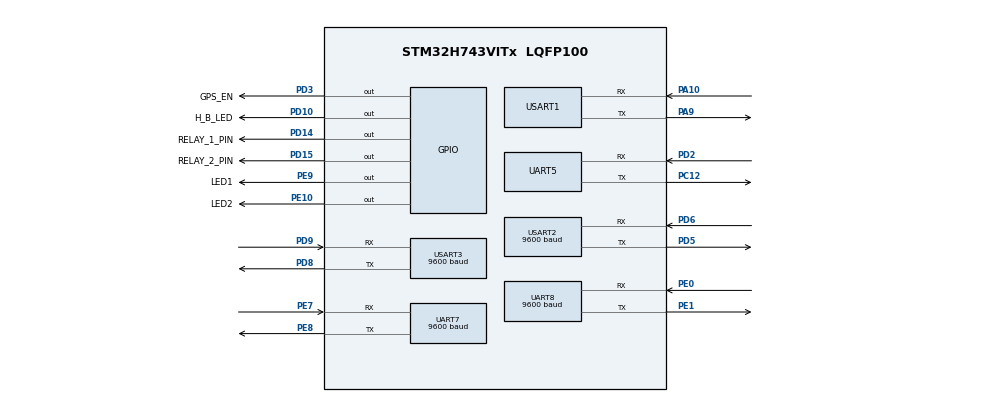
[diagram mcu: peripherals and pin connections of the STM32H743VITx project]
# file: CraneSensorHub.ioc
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CORTEX_M7.default_mode_Activation=1
Dma.Request0=UART7_RX
Dma.Request1=UART7_TX
Dma.Request2=USART1_RX
Dma.Request3=USART1_TX
Dma.Request4=USART2_RX
Dma.Request5=USART2_TX
Dma.Request6=UART5_RX
Dma.Request7=UART5_TX
Dma.UART5_RX.6.Direction=DMA_PERIPH_TO_MEMORY
Dma.UART5_RX.6.EventEnable=DISABLE
Dma.UART5_RX.6.FIFOMode=DMA_FIFOMODE_DISABLE
Dma.UART5_RX.6.Instance=DMA1_Stream6
Dma.UART5_RX.6.MemDataAlignment=DMA_MDATAALIGN_BYTE
Dma.UART5_RX.6.MemInc=DMA_MINC_ENABLE
Dma.UART5_RX.6.Mode=DMA_NORMAL
Dma.UART5_RX.6.PeriphDataAlignment=DMA_PDATAALIGN_BYTE
Dma.UART5_RX.6.PeriphInc=DMA_PINC_DISABLE
Dma.UART5_RX.6.Polarity=HAL_DMAMUX_REQ_GEN_RISING
Dma.UART5_RX.6.Priority=DMA_PRIORITY_LOW
Dma.UART5_RX.6.RequestNumber=1
Dma.UART5_RX.6.SignalID=NONE
Dma.UART5_RX.6.SyncEnable=DISABLE
Dma.UART5_RX.6.SyncPolarity=HAL_DMAMUX_SYNC_NO_EVENT
Dma.UART5_RX.6.SyncRequestNumber=1
Dma.UART5_RX.6.SyncSignalID=NONE
Dma.UART5_TX.7.Direction=DMA_MEMORY_TO_PERIPH
Dma.UART5_TX.7.EventEnable=DISABLE
Dma.UART5_TX.7.FIFOMode=DMA_FIFOMODE_DISABLE
Dma.UART5_TX.7.Instance=DMA1_Stream7
Dma.UART5_TX.7.MemDataAlignment=DMA_MDATAALIGN_BYTE
Dma.UART5_TX.7.MemInc=DMA_MINC_ENABLE
Dma.UART5_TX.7.Mode=DMA_NORMAL
Dma.UART5_TX.7.PeriphDataAlignment=DMA_PDATAALIGN_BYTE
Dma.UART5_TX.7.PeriphInc=DMA_PINC_DISABLE
Dma.UART5_TX.7.Polarity=HAL_DMAMUX_REQ_GEN_RISING
Dma.UART5_TX.7.Priority=DMA_PRIORITY_LOW
Dma.UART5_TX.7.RequestNumber=1
Dma.UART5_TX.7.SignalID=NONE
Dma.UART5_TX.7.SyncEnable=DISABLE
Dma.UART5_TX.7.SyncPolarity=HAL_DMAMUX_SYNC_NO_EVENT
Dma.UART5_TX.7.SyncRequestNumber=1
Dma.UART5_TX.7.SyncSignalID=NONE
Dma.UART7_RX.0.Direction=DMA_PERIPH_TO_MEMORY
Dma.UART7_RX.0.EventEnable=DISABLE
Dma.UART7_RX.0.FIFOMode=DMA_FIFOMODE_DISABLE
Dma.UART7_RX.0.Instance=DMA1_Stream0
Dma.UART7_RX.0.MemDataAlignment=DMA_MDATAALIGN_BYTE
Dma.UART7_RX.0.MemInc=DMA_MINC_ENABLE
Dma.UART7_RX.0.Mode=DMA_NORMAL
Dma.UART7_RX.0.PeriphDataAlignment=DMA_PDATAALIGN_BYTE
Dma.UART7_RX.0.PeriphInc=DMA_PINC_DISABLE
Dma.UART7_RX.0.Polarity=HAL_DMAMUX_REQ_GEN_RISING
Dma.UART7_RX.0.Priority=DMA_PRIORITY_HIGH
Dma.UART7_RX.0.RequestNumber=1
Dma.UART7_RX.0.SignalID=NONE
Dma.UART7_RX.0.SyncEnable=DISABLE
Dma.UART7_RX.0.SyncPolarity=HAL_DMAMUX_SYNC_NO_EVENT
Dma.UART7_RX.0.SyncRequestNumber=1
Dma.UART7_RX.0.SyncSignalID=NONE
Dma.UART7_TX.1.Direction=DMA_MEMORY_TO_PERIPH
Dma.UART7_TX.1.EventEnable=DISABLE
Dma.UART7_TX.1.FIFOMode=DMA_FIFOMODE_DISABLE
Dma.UART7_TX.1.Instance=DMA1_Stream1
Dma.UART7_TX.1.MemDataAlignment=DMA_MDATAALIGN_BYTE
Dma.UART7_TX.1.MemInc=DMA_MINC_ENABLE
Dma.UART7_TX.1.Mode=DMA_NORMAL
Dma.UART7_TX.1.PeriphDataAlignment=DMA_PDATAALIGN_BYTE
Dma.UART7_TX.1.PeriphInc=DMA_PINC_DISABLE
Dma.UART7_TX.1.Polarity=HAL_DMAMUX_REQ_GEN_RISING
Dma.UART7_TX.1.Priority=DMA_PRIORITY_LOW
Dma.UART7_TX.1.RequestNumber=1
Dma.UART7_TX.1.SignalID=NONE
Dma.UART7_TX.1.SyncEnable=DISABLE
Dma.UART7_TX.1.SyncPolarity=HAL_DMAMUX_SYNC_NO_EVENT
Dma.UART7_TX.1.SyncRequestNumber=1
Dma.UART7_TX.1.SyncSignalID=NONE
Dma.USART1_RX.2.Direction=DMA_PERIPH_TO_MEMORY
Dma.USART1_RX.2.EventEnable=DISABLE
Dma.USART1_RX.2.FIFOMode=DMA_FIFOMODE_DISABLE
Dma.USART1_RX.2.Instance=DMA1_Stream2
Dma.USART1_RX.2.MemDataAlignment=DMA_MDATAALIGN_BYTE
Dma.USART1_RX.2.MemInc=DMA_MINC_ENABLE
Dma.USART1_RX.2.Mode=DMA_NORMAL
Dma.USART1_RX.2.PeriphDataAlignment=DMA_PDATAALIGN_BYTE
Dma.USART1_RX.2.PeriphInc=DMA_PINC_DISABLE
Dma.USART1_RX.2.Polarity=HAL_DMAMUX_REQ_GEN_RISING
Dma.USART1_RX.2.Priority=DMA_PRIORITY_LOW
Dma.USART1_RX.2.RequestNumber=1
Dma.USART1_RX.2.SignalID=NONE
Dma.USART1_RX.2.SyncEnable=DISABLE
Dma.USART1_RX.2.SyncPolarity=HAL_DMAMUX_SYNC_NO_EVENT
Dma.USART1_RX.2.SyncRequestNumber=1
Dma.USART1_RX.2.SyncSignalID=NONE
Dma.USART1_TX.3.Direction=DMA_MEMORY_TO_PERIPH
Dma.USART1_TX.3.EventEnable=DISABLE
Dma.USART1_TX.3.FIFOMode=DMA_FIFOMODE_DISABLE
Dma.USART1_TX.3.Instance=DMA1_Stream3
Dma.USART1_TX.3.MemDataAlignment=DMA_MDATAALIGN_BYTE
Dma.USART1_TX.3.MemInc=DMA_MINC_ENABLE
Dma.USART1_TX.3.Mode=DMA_NORMAL
Dma.USART1_TX.3.PeriphDataAlignment=DMA_PDATAALIGN_BYTE
Dma.USART1_TX.3.PeriphInc=DMA_PINC_DISABLE
Dma.USART1_TX.3.Polarity=HAL_DMAMUX_REQ_GEN_RISING
Dma.USART1_TX.3.Priority=DMA_PRIORITY_LOW
Dma.USART1_TX.3.RequestNumber=1
Dma.USART1_TX.3.SignalID=NONE
Dma.USART1_TX.3.SyncEnable=DISABLE
Dma.USART1_TX.3.SyncPolarity=HAL_DMAMUX_SYNC_NO_EVENT
Dma.USART1_TX.3.SyncRequestNumber=1
Dma.USART1_TX.3.SyncSignalID=NONE
Dma.USART2_RX.4.Direction=DMA_PERIPH_TO_MEMORY
Dma.USART2_RX.4.EventEnable=DISABLE
Dma.USART2_RX.4.FIFOMode=DMA_FIFOMODE_DISABLE
Dma.USART2_RX.4.Instance=DMA1_Stream4
Dma.USART2_RX.4.MemDataAlignment=DMA_MDATAALIGN_BYTE
Dma.USART2_RX.4.MemInc=DMA_MINC_ENABLE
Dma.USART2_RX.4.Mode=DMA_NORMAL
Dma.USART2_RX.4.PeriphDataAlignment=DMA_PDATAALIGN_BYTE
Dma.USART2_RX.4.PeriphInc=DMA_PINC_DISABLE
Dma.USART2_RX.4.Polarity=HAL_DMAMUX_REQ_GEN_RISING
Dma.USART2_RX.4.Priority=DMA_PRIORITY_LOW
Dma.USART2_RX.4.RequestNumber=1
Dma.USART2_RX.4.SignalID=NONE
Dma.USART2_RX.4.SyncEnable=DISABLE
Dma.USART2_RX.4.SyncPolarity=HAL_DMAMUX_SYNC_NO_EVENT
Dma.USART2_RX.4.SyncRequestNumber=1
Dma.USART2_RX.4.SyncSignalID=NONE
Dma.USART2_TX.5.Direction=DMA_MEMORY_TO_PERIPH
Dma.USART2_TX.5.EventEnable=DISABLE
Dma.USART2_TX.5.FIFOMode=DMA_FIFOMODE_DISABLE
Dma.USART2_TX.5.Instance=DMA1_Stream5
Dma.USART2_TX.5.MemDataAlignment=DMA_MDATAALIGN_BYTE
Dma.USART2_TX.5.MemInc=DMA_MINC_ENABLE
Dma.USART2_TX.5.Mode=DMA_NORMAL
Dma.USART2_TX.5.PeriphDataAlignment=DMA_PDATAALIGN_BYTE
Dma.USART2_TX.5.PeriphInc=DMA_PINC_DISABLE
Dma.USART2_TX.5.Polarity=HAL_DMAMUX_REQ_GEN_RISING
Dma.USART2_TX.5.Priority=DMA_PRIORITY_LOW
Dma.USART2_TX.5.RequestNumber=1
Dma.USART2_TX.5.SignalID=NONE
Dma.USART2_TX.5.SyncEnable=DISABLE
Dma.USART2_TX.5.SyncPolarity=HAL_DMAMUX_SYNC_NO_EVENT
Dma.USART2_TX.5.SyncRequestNumber=1
Dma.USART2_TX.5.SyncSignalID=NONE
FREERTOS.Tasks01=defaultTask,24,128,StartDefaultTask,Default,NULL,Dynamic,NULL,NULL
FREERTOS.configUSE_NEWLIB_REENTRANT=1
Mcu.Family=STM32H7
Mcu.Name=STM32H743VITx
Mcu.Package=LQFP100
NVIC.DMA1_Stream0_IRQn=true\:5\:0\:false\:false\:true\:true\:false\:true\:true
NVIC.DMA1_Stream1_IRQn=true\:5\:0\:false\:false\:true\:true\:false\:true\:true
NVIC.DMA1_Stream2_IRQn=true\:5\:0\:false\:false\:true\:true\:false\:true\:true
NVIC.DMA1_Stream3_IRQn=true\:5\:0\:false\:false\:true\:true\:false\:true\:true
NVIC.DMA1_Stream4_IRQn=true\:5\:0\:false\:false\:true\:true\:false\:true\:true
NVIC.DMA1_Stream5_IRQn=true\:5\:0\:false\:false\:true\:true\:false\:true\:true
NVIC.DMA1_Stream6_IRQn=true\:5\:0\:false\:false\:true\:true\:false\:true\:true
NVIC.DMA1_Stream7_IRQn=true\:5\:0\:false\:false\:true\:true\:false\:true\:true
NVIC.PriorityGroup=NVIC_PRIORITYGROUP_4
NVIC.RTC_Alarm_IRQn=true\:5\:0\:false\:false\:true\:true\:true\:true\:true
NVIC.TIM6_DAC_IRQn=true\:15\:0\:false\:false\:true\:false\:false\:true\:true
NVIC.TimeBase=TIM6_DAC_IRQn
NVIC.TimeBaseIP=TIM6
NVIC.UART5_IRQn=true\:5\:0\:false\:false\:true\:true\:true\:true\:true
NVIC.UART7_IRQn=true\:5\:0\:false\:false\:true\:true\:true\:true\:true
NVIC.UART8_IRQn=true\:5\:0\:false\:false\:true\:true\:true\:true\:true
NVIC.USART1_IRQn=true\:5\:0\:false\:false\:true\:true\:true\:true\:true
NVIC.USART2_IRQn=true\:5\:0\:false\:false\:true\:true\:true\:true\:true
NVIC.USART3_IRQn=true\:5\:0\:false\:false\:true\:true\:true\:true\:true
PA10.Mode=Asynchronous
PA10.Signal=USART1_RX
PA9.Mode=Asynchronous
PA9.Signal=USART1_TX
PC12.Mode=Asynchronous
PC12.Signal=UART5_TX
PC14-OSC32_IN\ (OSC32_IN).Mode=LSE-External-Oscillator
PC14-OSC32_IN\ (OSC32_IN).Signal=RCC_OSC32_IN
PC15-OSC32_OUT\ (OSC32_OUT).Mode=LSE-External-Oscillator
PC15-OSC32_OUT\ (OSC32_OUT).Signal=RCC_OSC32_OUT
PD10.GPIO_Label=H_B_LED
PD10.Signal=GPIO_Output
PD14.GPIO_Label=RELAY_1_PIN
PD14.Signal=GPIO_Output
PD15.GPIO_Label=RELAY_2_PIN
PD15.Signal=GPIO_Output
PD2.Mode=Asynchronous
PD2.Signal=UART5_RX
PD3.GPIO_Label=GPS_EN
PD3.PinState=GPIO_PIN_SET
PD3.Signal=GPIO_Output
PD5.Mode=Asynchronous
PD5.Signal=USART2_TX
PD6.Mode=Asynchronous
PD6.Signal=USART2_RX
PD8.Mode=Asynchronous
PD8.Signal=USART3_TX
PD9.Mode=Asynchronous
PD9.Signal=USART3_RX
PE0.Mode=Asynchronous
PE0.Signal=UART8_RX
PE1.Mode=Asynchronous
PE1.Signal=UART8_TX
PE10.GPIO_Label=LED2
PE10.Signal=GPIO_Output
PE7.Mode=Asynchronous
PE7.Signal=UART7_RX
PE8.Mode=Asynchronous
PE8.Signal=UART7_TX
PE9.GPIO_Label=LED1
PE9.Signal=GPIO_Output
PH0-OSC_IN\ (PH0).Mode=HSE-External-Oscillator
PH0-OSC_IN\ (PH0).Signal=RCC_OSC_IN
PH1-OSC_OUT\ (PH1).Mode=HSE-External-Oscillator
PH1-OSC_OUT\ (PH1).Signal=RCC_OSC_OUT
ProjectManager.HeapSize=0x4000
ProjectManager.StackSize=0x4000
ProjectManager.TargetToolchain=STM32CubeIDE
RCC.ADCFreq_Value=50390625
RCC.APB1Freq_Value=120000000
RCC.APB2Freq_Value=120000000
RCC.APB3Freq_Value=120000000
RCC.APB4Freq_Value=120000000
RCC.CortexFreq_Value=480000000
RCC.D1PPRE=RCC_APB3_DIV2
RCC.D2PPRE1=RCC_APB1_DIV2
RCC.D2PPRE2=RCC_APB2_DIV2
RCC.D3PPRE=RCC_APB4_DIV2
RCC.DIVM1=5
RCC.DIVN1=192
RCC.HCLKFreq_Value=240000000
RCC.HPRE=RCC_HCLK_DIV2
RCC.PLLSourceVirtual=RCC_PLLSOURCE_HSE
RCC.RTCClockSelection=RCC_RTCCLKSOURCE_LSE
RCC.SYSCLKFreq_VALUE=480000000
RCC.SYSCLKSource=RCC_SYSCLKSOURCE_PLLCLK
RCC.USBFreq_Value=480000000
RTC.AlarmMaskDateWeekDay_B-Alarm\ B=RTC_ALARMMASK_DATEWEEKDAY
RTC.Alarm_B-Alarm\ B=RTC_ALARM_B
RTC.Format=RTC_FORMAT_BIN
UART7.BaudRate=9600
UART8.BaudRate=9600
USART1.VirtualMode-Asynchronous=VM_ASYNC
USART2.BaudRate=9600
USART2.VirtualMode-Asynchronous=VM_ASYNC
USART3.BaudRate=9600
USART3.VirtualMode-Asynchronous=VM_ASYNC
VP_FREERTOS_VS_CMSIS_V2.Mode=CMSIS_V2
VP_MEMORYMAP_VS_MEMORYMAP.Mode=CurAppReg
VP_RTC_VS_RTC_Activate.Mode=RTC_Enabled
VP_RTC_VS_RTC_Alarm_B_Intern.Mode=Alarm B
VP_RTC_VS_RTC_Calendar.Mode=RTC_Calendar
VP_SYS_VS_tim6.Mode=TIM6
board=custom

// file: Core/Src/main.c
/* USER CODE BEGIN Header */
/**
  ******************************************************************************
  * @file           : main.c
  * @brief          : Main program body
  ******************************************************************************
  * @attention
  *
  * Copyright (c) 2025 STMicroelectronics.
  * All rights reserved.
  *
  * This software is licensed under terms that can be found in the LICENSE file
  * in the root directory of this software component.
  * If no LICENSE file comes with this software, it is provided AS-IS.
  *
  ******************************************************************************
  */
/* USER CODE END Header */
#include "main.h"
#include "cmsis_os.h"
#include "dma.h"
#include "rtc.h"
#include "usart.h"
#include "gpio.h"

/* USER CODE BEGIN Includes */
#include "board.h"
#include "printf_redirect.h"
/* USER CODE END Includes */

void SystemClock_Config(void);
static void MPU_Config(void);
void MX_FREERTOS_Init(void);

int main(void)
{

  /* MPU Configuration--------------------------------------------------------*/
  MPU_Config();

  /* MCU Configuration--------------------------------------------------------*/

  /* Reset of all peripherals, Initializes the Flash interface and the Systick. */
  HAL_Init();

  /* Configure the system clock */
  SystemClock_Config();

  /* Initialize all configured peripherals */
  MX_GPIO_Init();
  MX_DMA_Init();
  MX_USART1_UART_Init();
  MX_UART7_Init();
  MX_UART8_Init();
  MX_USART2_UART_Init();
  MX_USART3_UART_Init();
  MX_UART5_Init();
  MX_RTC_Init();
  /* USER CODE BEGIN 2 */
  init_app();
  /* USER CODE END 2 */

  /* Init scheduler */
  osKernelInitialize();  /* Call init function for freertos objects (in cmsis_os2.c) */
  MX_FREERTOS_Init();

  /* Start scheduler */
  osKernelStart();

  /* We should never get here as control is now taken by the scheduler */

  /* Infinite loop */
  while (1)
  {

    /* USER CODE BEGIN 3 */
    Error_Handler();
  }
  /* USER CODE END 3 */
}

void SystemClock_Config(void)
{
  RCC_OscInitTypeDef RCC_OscInitStruct = {0};
  RCC_ClkInitTypeDef RCC_ClkInitStruct = {0};

  /** Supply configuration update enable
  */
  HAL_PWREx_ConfigSupply(PWR_LDO_SUPPLY);

  /** Configure the main internal regulator output voltage
  */
  __HAL_PWR_VOLTAGESCALING_CONFIG(PWR_REGULATOR_VOLTAGE_SCALE0);

  while(!__HAL_PWR_GET_FLAG(PWR_FLAG_VOSRDY)) {}

  /** Configure LSE Drive Capability
  */
  HAL_PWR_EnableBkUpAccess();
  __HAL_RCC_LSEDRIVE_CONFIG(RCC_LSEDRIVE_LOW);

  /** Initializes the RCC Oscillators according to the specified parameters
  * in the RCC_OscInitTypeDef structure.
  */
  RCC_OscInitStruct.OscillatorType = RCC_OSCILLATORTYPE_HSE|RCC_OSCILLATORTYPE_LSE;
  RCC_OscInitStruct.HSEState = RCC_HSE_ON;
  RCC_OscInitStruct.LSEState = RCC_LSE_ON;
  RCC_OscInitStruct.PLL.PLLState = RCC_PLL_ON;
  RCC_OscInitStruct.PLL.PLLSource = RCC_PLLSOURCE_HSE;
  RCC_OscInitStruct.PLL.PLLM = 5;
  RCC_OscInitStruct.PLL.PLLN = 192;
  RCC_OscInitStruct.PLL.PLLP = 2;
  RCC_OscInitStruct.PLL.PLLQ = 2;
  RCC_OscInitStruct.PLL.PLLR = 2;
  RCC_OscInitStruct.PLL.PLLRGE = RCC_PLL1VCIRANGE_2;
  RCC_OscInitStruct.PLL.PLLVCOSEL = RCC_PLL1VCOWIDE;
  RCC_OscInitStruct.PLL.PLLFRACN = 0;
  if (HAL_RCC_OscConfig(&RCC_OscInitStruct) != HAL_OK)
  {
    Error_Handler();
  }

  /** Initializes the CPU, AHB and APB buses clocks
  */
  RCC_ClkInitStruct.ClockType = RCC_CLOCKTYPE_HCLK|RCC_CLOCKTYPE_SYSCLK
                              |RCC_CLOCKTYPE_PCLK1|RCC_CLOCKTYPE_PCLK2
                              |RCC_CLOCKTYPE_D3PCLK1|RCC_CLOCKTYPE_D1PCLK1;
  RCC_ClkInitStruct.SYSCLKSource = RCC_SYSCLKSOURCE_PLLCLK;
  RCC_ClkInitStruct.SYSCLKDivider = RCC_SYSCLK_DIV1;
  RCC_ClkInitStruct.AHBCLKDivider = RCC_HCLK_DIV2;
  RCC_ClkInitStruct.APB3CLKDivider = RCC_APB3_DIV2;
  RCC_ClkInitStruct.APB1CLKDivider = RCC_APB1_DIV2;
  RCC_ClkInitStruct.APB2CLKDivider = RCC_APB2_DIV2;
  RCC_ClkInitStruct.APB4CLKDivider = RCC_APB4_DIV2;

  if (HAL_RCC_ClockConfig(&RCC_ClkInitStruct, FLASH_LATENCY_4) != HAL_OK)
  {
    Error_Handler();
  }
}

 /* MPU Configuration */

void MPU_Config(void)
{
  MPU_Region_InitTypeDef MPU_InitStruct = {0};

  /* Disables the MPU */
  HAL_MPU_Disable();

  /** Initializes and configures the Region and the memory to be protected
  */
  MPU_InitStruct.Enable = MPU_REGION_ENABLE;
  MPU_InitStruct.Number = MPU_REGION_NUMBER0;
  MPU_InitStruct.BaseAddress = 0x0;
  MPU_InitStruct.Size = MPU_REGION_SIZE_4GB;
  MPU_InitStruct.SubRegionDisable = 0x87;
  MPU_InitStruct.TypeExtField = MPU_TEX_LEVEL0;
  MPU_InitStruct.AccessPermission = MPU_REGION_NO_ACCESS;
  MPU_InitStruct.DisableExec = MPU_INSTRUCTION_ACCESS_DISABLE;
  MPU_InitStruct.IsShareable = MPU_ACCESS_SHAREABLE;
  MPU_InitStruct.IsCacheable = MPU_ACCESS_NOT_CACHEABLE;
  MPU_InitStruct.IsBufferable = MPU_ACCESS_NOT_BUFFERABLE;

  HAL_MPU_ConfigRegion(&MPU_InitStruct);
  /* Enables the MPU */
  HAL_MPU_Enable(MPU_PRIVILEGED_DEFAULT);

}

void HAL_TIM_PeriodElapsedCallback(TIM_HandleTypeDef *htim)
{
  if (htim->Instance == TIM6)
  {
    HAL_IncTick();
  }
}

void Error_Handler(void)
{
  /* USER CODE BEGIN Error_Handler_Debug */
  /* User can add his own implementation to report the HAL error return state */
  __disable_irq();
  __set_FAULTMASK(1);
  NVIC_SystemReset();
  while (1)
  {

  }
  /* USER CODE END Error_Handler_Debug */
}
